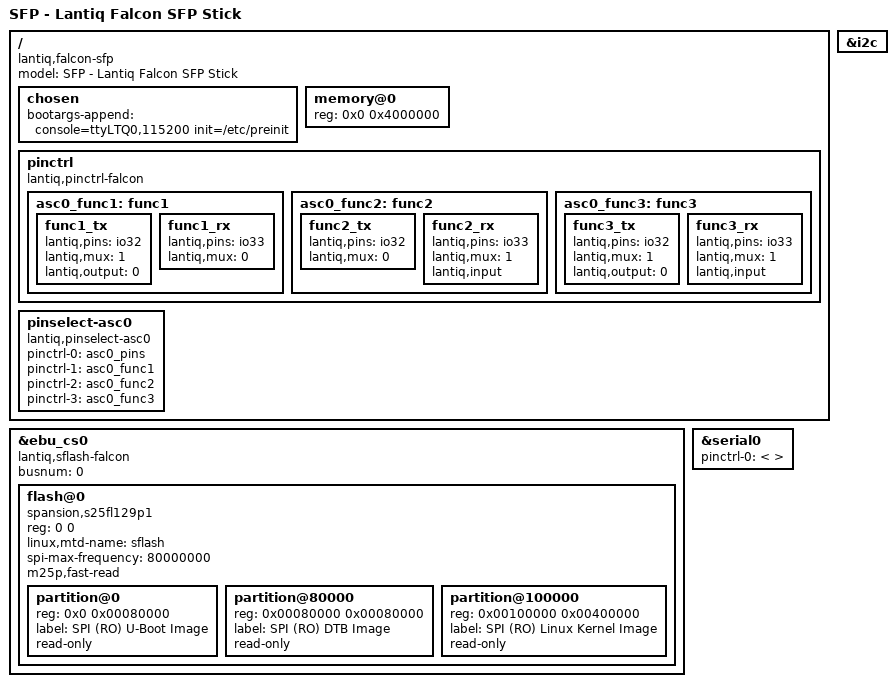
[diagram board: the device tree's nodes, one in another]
/dts-v1/;

/include/ "falcon.dtsi"

/ {
	model = "SFP - Lantiq Falcon SFP Stick";
	compatible = "lantiq,falcon-sfp", "lantiq,falcon";

	chosen {
		bootargs-append = "console=ttyLTQ0,115200 init=/etc/preinit";
	};

	memory@0 {
		reg = <0x0 0x4000000>;  // 64M at 0x0
	};

	pinctrl {
		compatible = "lantiq,pinctrl-falcon";

		asc0_func1: func1 {
			func1_tx {
				lantiq,pins = "io32";
				lantiq,mux = <1>;
				lantiq,output = <0>;
			};
			func1_rx {
				lantiq,pins = "io33";
				lantiq,mux = <0>;
			};
		};
		asc0_func2: func2 {
			func2_tx {
				lantiq,pins = "io32";
				lantiq,mux = <0>;
			};
			func2_rx {
				lantiq,pins = "io33";
				lantiq,mux = <1>;
				lantiq,input;
			};
		};
		asc0_func3: func3 {
			func3_tx {
				lantiq,pins = "io32";
				lantiq,mux = <1>;
				lantiq,output = <0>;
			};
			func3_rx {
				lantiq,pins = "io33";
				lantiq,mux = <1>;
				lantiq,input;
			};
		};
	};

	pinselect-asc0 {
		compatible = "lantiq,pinselect-asc0";
		pinctrl-names = "asc0", "func1", "func2", "func3";
		pinctrl-0 = <&asc0_pins>;
		pinctrl-1 = <&asc0_func1>;
		pinctrl-2 = <&asc0_func2>;
		pinctrl-3 = <&asc0_func3>;
	};
};

&ebu_cs0 {
	#address-cells = <1>;
	#size-cells = <1>;
	compatible = "lantiq,sflash-falcon", "simple-bus";
	busnum = <0>;

	flash@0 {
		#address-cells = <1>;
		#size-cells = <1>;
		compatible = "spansion,s25fl129p1";
		reg = <0 0>;
		linux,mtd-name = "sflash";
		spi-max-frequency = <80000000>;
		m25p,fast-read;

		partition@0 {
			reg = <0x0 0x00080000>;
			label = "SPI (RO) U-Boot Image";
			read-only;
		};

		partition@80000 {
			reg = <0x00080000 0x00080000>;
			label = "SPI (RO) DTB Image";
			read-only;
		};

		partition@100000 {
			reg = <0x00100000 0x00400000>;
			label = "SPI (RO) Linux Kernel Image";
			read-only;
		};
	};
};

&serial0 {
	pinctrl-names = "default";
	/* use "empty" pinctrl to leave setting from u-boot enabled */
	pinctrl-0 = < >;
};

&i2c {
	status = "okay";
};
